# MKW31Z4 register map
Vendor: Freescale Semiconductor, Inc.; Series: Kinetis_W; File version: 1.6
CPU: CM0PLUS r0p0, little endian, no MPU, no FPU, VTOR, 2 interrupt priority bits
Registers are 16-bit, read-write, no defined reset value unless marked. A register's access mark holds for its fields unless they carry their own. Offsets are from the block's base; [hi:lo] are bit positions; {n}, {i} and the like mark numbered series; 'fields as' and 'values as' point back to an identical list.

## TPM0 — Timer/PWM Module
Base 0x40038000; register names take the prefix TPM0_
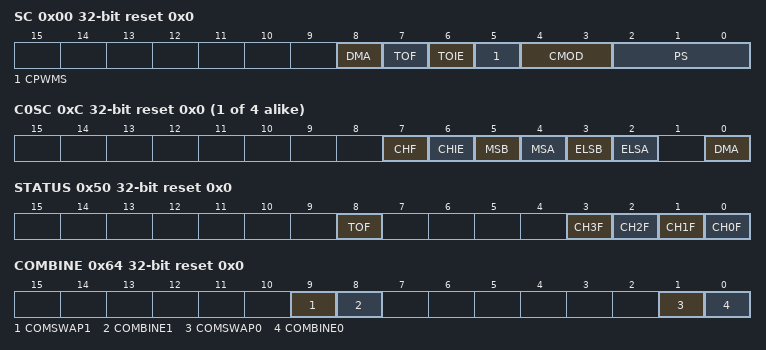
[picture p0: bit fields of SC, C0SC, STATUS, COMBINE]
0x00 SC 32-bit reset 0x0 — Status and Control
  [8] DMA — DMA Enable
    0=Disables DMA transfers; 1=Enables DMA transfers
  [7] TOF — Timer Overflow Flag
    0=TPM counter has not overflowed; 1=TPM counter has overflowed
  [6] TOIE — Timer Overflow Interrupt Enable
    0=Disable TOF interrupts. Use software polling or DMA request.; 1=Enable TOF interrupts. An interrupt is generated when TOF equals one.
  [5] CPWMS — Center-Aligned PWM Select
    0=TPM counter operates in up counting mode; 1=TPM counter operates in up-down counting mode
  [4:3] CMOD — Clock Mode Selection
    0=TPM counter is disabled; 1=TPM counter increments on every TPM counter clock; 2=TPM counter increments on rising edge of TPM_EXTCLK synchronized to the TPM counter clock
  [2:0] PS — Prescale Factor Selection
    0=Divide by 1; 1=Divide by 2; 2=Divide by 4; 3=Divide by 8; 4=Divide by 16; 5=Divide by 32; 6=Divide by 64; 7=Divide by 128
0x04 CNT 32-bit reset 0x0 — Counter
  [15:0] COUNT — Counter value
0x08 MOD 32-bit reset 0xFFFF — Modulo
  [15:0] MOD — Modulo value
{0xC+8i} C{i}SC (i=0..3) 32-bit reset 0x0 — Channel (n) Status and Control
  [7] CHF — Channel Flag
    0=No channel event has occurred; 1=A channel event has occurred
  [6] CHIE — Channel Interrupt Enable
    0=Disable channel interrupts; 1=Enable channel interrupts
  [5] MSB — Channel Mode Select
  [4] MSA — Channel Mode Select
  [3] ELSB — Edge or Level Select
  [2] ELSA — Edge or Level Select
  [0] DMA — DMA Enable
    0=Disable DMA transfers; 1=Enable DMA transfers
{0x10+8i} C{i}V (i=0..3) 32-bit reset 0x0 — Channel (n) Value
  [15:0] VAL — Channel Value
0x50 STATUS 32-bit reset 0x0 — Capture and Compare Status
  [8] TOF — Timer Overflow Flag
    values as SC.TOF
  [n] CH{n}F (n=0..3) — Channel {n} Flag
    values as C0SC.CHF
0x64 COMBINE 32-bit reset 0x0 — Combine Channel Register
  [9] COMSWAP1 — Combine Channels 2 and 3 Swap
    0=Even channel is used for input capture and 1st compare; 1=Odd channel is used for input capture and 1st compare
  [8] COMBINE1 — Combine Channels 2 and 3
    0=Channels 2 and 3 are independent; 1=Channels 2 and 3 are combined
  [1] COMSWAP0 — Combine Channel 0 and 1 Swap
    values as COMSWAP1
  [0] COMBINE0 — Combine Channels 0 and 1
    0=Channels 0 and 1 are independent; 1=Channels 0 and 1 are combined
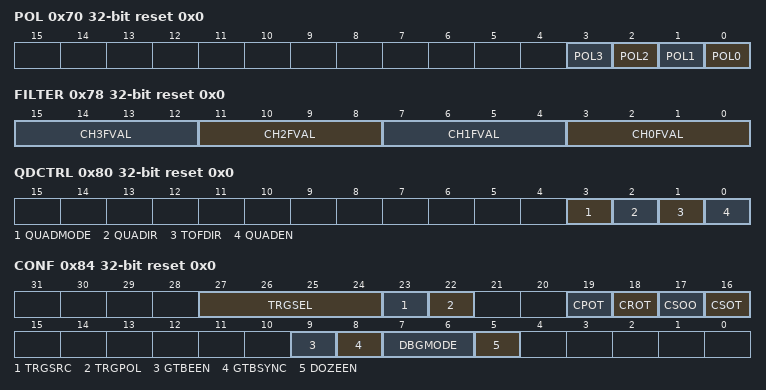
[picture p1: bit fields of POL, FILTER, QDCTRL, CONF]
0x70 POL 32-bit reset 0x0 — Channel Polarity
  [all] fields
    0=The channel polarity is active high; 1=The channel polarity is active low
  [n] POL{n} (n=0..3) — Channel {n} Polarity
0x78 FILTER 32-bit reset 0x0 — Filter Control
  [4n+3:4n] CH{n}FVAL (n=0..3) — Channel {n} Filter Value
0x80 QDCTRL 32-bit reset 0x0 — Quadrature Decoder Control and Status
  [3] QUADMODE — Quadrature Decoder Mode
    0=Phase encoding mode; 1=Count and direction encoding mode
  [2] QUADIR ro — Counter Direction in Quadrature Decode Mode
    0=Counter direction is decreasing (counter decrement); 1=Counter direction is increasing (counter increment)
  [1] TOFDIR ro — Indicates if the TOF bit was set on the top or the bottom of counting.
    0=TOF bit was set on the bottom of counting. There was an FTM counter decrement and FTM counter changes from its minimum value (zero) to its maximum value (MOD register).; 1=TOF bit was set on the top of counting. There was an FTM counter increment and FTM counter changes from its maximum value (MOD register) to its minimum value (zero).
  [0] QUADEN — Enables the quadrature decoder mode
    0=Quadrature decoder mode is disabled; 1=Quadrature decoder mode is enabled
0x84 CONF 32-bit reset 0x0 — Configuration
  [27:24] TRGSEL — Trigger Select
    1=Channel 0 pin input capture; 2=Channel 1 pin input capture; 3=Channel 0 or Channel 1 pin input capture; 4=Channel 2 pin input capture; 5=Channel 0 or Channel 2 pin input capture; 6=Channel 1 or Channel 2 pin input capture; 7=Channel 0 or Channel 1 or Channel 2 pin input capture; 8=Channel 3 pin input capture; 9=Channel 0 or Channel 3 pin input capture; 10=Channel 1 or Channel 3 pin input capture; 11=Channel 0 or Channel 1 or Channel 3 pin input capture; 12=Channel 2 or Channel 3 pin input capture; 13=Channel 0 or Channel 2 or Channel 3 pin input capture; 14=Channel 1 or Channel 2 or Channel 3 pin input capture; 15=Channel 0 or Channel 1 or Channel 2 or Channel 3 pin input capture
  [23] TRGSRC — Trigger Source
    0=Trigger source selected by TRGSEL is external; 1=Trigger source selected by TRGSEL is internal (channel pin input capture)
  [22] TRGPOL — Trigger Polarity
    0=Trigger is active high; 1=Trigger is active low
  [19] CPOT — Counter Pause On Trigger
  [18] CROT — Counter Reload On Trigger
    0=Counter is not reloaded due to a rising edge on the selected input trigger; 1=Counter is reloaded when a rising edge is detected on the selected input trigger
  [17] CSOO — Counter Stop On Overflow
    0=TPM counter continues incrementing or decrementing after overflow; 1=TPM counter stops incrementing or decrementing after overflow
  [16] CSOT — Counter Start on Trigger
    0=TPM counter starts to increment immediately, once it is enabled; 1=TPM counter only starts to increment when it a rising edge on the selected input trigger is detected, after it has been enabled or after it has stopped due to overflow
  [9] GTBEEN — Global time base enable
    0=All channels use the internally generated TPM counter as their timebase; 1=All channels use an externally generated global timebase as their timebase
  [8] GTBSYNC — Global Time Base Synchronization
    0=Global timebase synchronization disabled; 1=Global timebase synchronization enabled
  [7:6] DBGMODE — Debug Mode
    0=TPM counter is paused and does not increment during debug mode. Trigger inputs and input capture events are also ignored.; 3=TPM counter continues in debug mode
  [5] DOZEEN — Doze Enable
    0=Internal TPM counter continues in Doze mode; 1=Internal TPM counter is paused and does not increment during Doze mode. Trigger inputs and input capture events are also ignored.

## TPM1 — Timer/PWM Module
Base 0x40039000; register names take the prefix TPM1_
Registers as TPM0, without C*SC, C*V; these are added or differ:
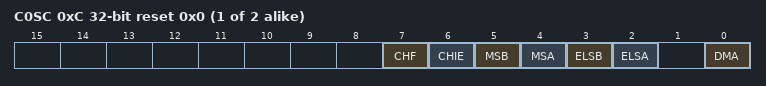
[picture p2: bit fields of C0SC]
{0xC+8i} C{i}SC (i=0..1) 32-bit reset 0x0 — Channel (n) Status and Control
  fields as TPM0.C0SC
{0x10+8i} C{i}V (i=0..1) 32-bit reset 0x0 — Channel (n) Value
  [15:0] VAL — Channel Value

## TPM2 — Timer/PWM Module
Base 0x4003A000; register names take the prefix TPM2_
Registers as TPM1.

## Notices in the file
Redistribution and use in source and binary forms, with or without modification,
are permitted provided that the following conditions are met:
o Redistributions of source code must retain the above copyright notice, this list
of conditions and the following disclaimer.
o Redistributions in binary form must reproduce the above copyright notice, this
list of conditions and the following disclaimer in the documentation and/or
other materials provided with the distribution.
o Neither the name of Freescale Semiconductor, Inc. nor the names of its
contributors may be used to endorse or promote products derived from this
software without specific prior written permission.
THIS SOFTWARE IS PROVIDED BY THE COPYRIGHT HOLDERS AND CONTRIBUTORS "AS IS" AND
ANY EXPRESS OR IMPLIED WARRANTIES, INCLUDING, BUT NOT LIMITED TO, THE IMPLIED
WARRANTIES OF MERCHANTABILITY AND FITNESS FOR A PARTICULAR PURPOSE ARE
DISCLAIMED. IN NO EVENT SHALL THE COPYRIGHT HOLDER OR CONTRIBUTORS BE LIABLE FOR
ANY DIRECT, INDIRECT, INCIDENTAL, SPECIAL, EXEMPLARY, OR CONSEQUENTIAL DAMAGES
(INCLUDING, BUT NOT LIMITED TO, PROCUREMENT OF SUBSTITUTE GOODS OR SERVICES;
LOSS OF USE, DATA, OR PROFITS; OR BUSINESS INTERRUPTION) HOWEVER CAUSED AND ON
ANY THEORY OF LIABILITY, WHETHER IN CONTRACT, STRICT LIABILITY, OR TORT
(INCLUDING NEGLIGENCE OR OTHERWISE) ARISING IN ANY WAY OUT OF THE USE OF THIS
SOFTWARE, EVEN IF ADVISED OF THE POSSIBILITY OF SUCH DAMAGE.
